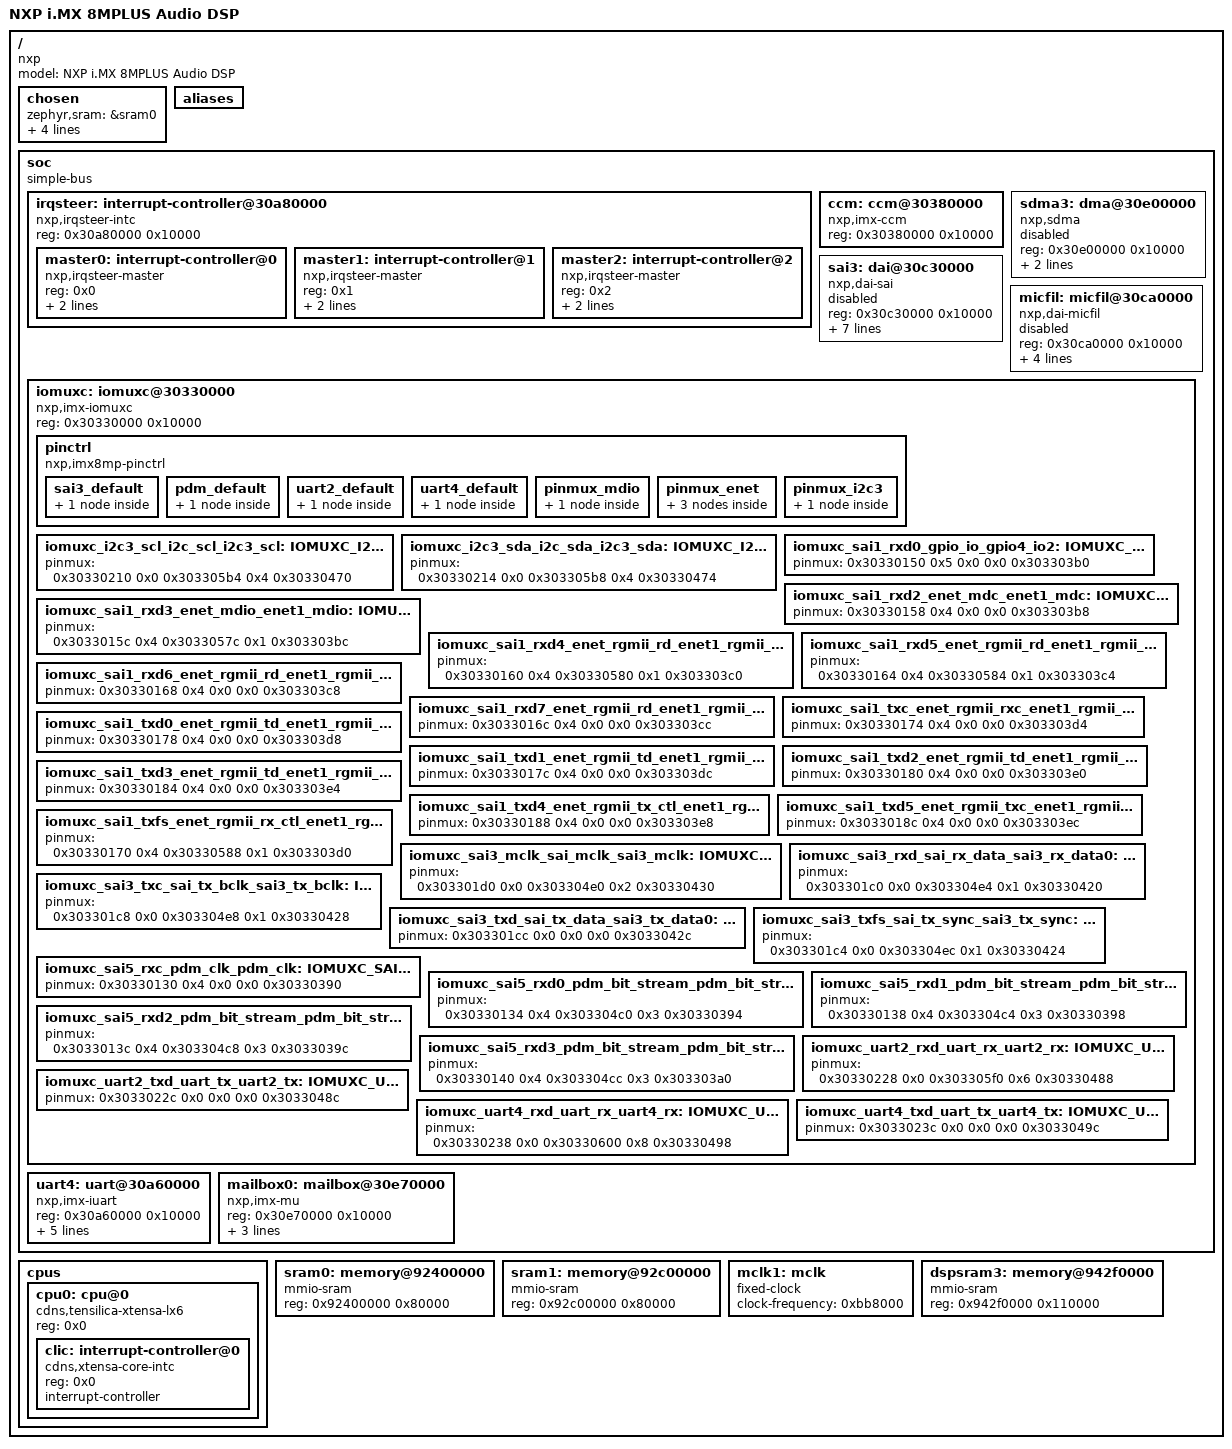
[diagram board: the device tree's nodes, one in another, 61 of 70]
/dts-v1/;

/ {
	#address-cells = < 0x1 >;
	#size-cells = < 0x1 >;
	model = "NXP i.MX 8MPLUS Audio DSP";
	compatible = "nxp";
	chosen {
		zephyr,sram = &sram0;
		zephyr,console = &uart4;
		zephyr,shell-uart = &uart4;
		zephyr,ipc_shm = &dspsram3;
		zephyr,ipc = &mailbox0;
	};
	aliases {
	};
	soc {
		#address-cells = < 0x1 >;
		#size-cells = < 0x1 >;
		compatible = "simple-bus";
		ranges;
		irqsteer: interrupt-controller@30a80000 {
			compatible = "nxp,irqsteer-intc";
			reg = < 0x30a80000 0x10000 >;
			#size-cells = < 0x0 >;
			#address-cells = < 0x1 >;
			master0: interrupt-controller@0 {
				compatible = "nxp,irqsteer-master";
				reg = < 0x0 >;
				interrupt-controller;
				#interrupt-cells = < 0x1 >;
				interrupts-extended = < &clic 0x13 0x0 0x0 >;
				phandle = < 0x26 >;
			};
			master1: interrupt-controller@1 {
				compatible = "nxp,irqsteer-master";
				reg = < 0x1 >;
				interrupt-controller;
				#interrupt-cells = < 0x1 >;
				interrupts-extended = < &clic 0x14 0x0 0x0 >;
				phandle = < 0x2 >;
			};
			master2: interrupt-controller@2 {
				compatible = "nxp,irqsteer-master";
				reg = < 0x2 >;
				interrupt-controller;
				#interrupt-cells = < 0x1 >;
				interrupts-extended = < &clic 0x15 0x0 0x0 >;
			};
		};
		ccm: ccm@30380000 {
			compatible = "nxp,imx-ccm";
			reg = < 0x30380000 0x10000 >;
			#clock-cells = < 0x3 >;
			phandle = < 0x27 >;
		};
		sdma3: dma@30e00000 {
			compatible = "nxp,sdma";
			reg = < 0x30e00000 0x10000 >;
			interrupt-parent = < &master1 >;
			interrupts = < 0x2 0x0 0x0 >;
			#dma-cells = < 0x2 >;
			status = "disabled";
			phandle = < 0x4 >;
		};
		sai3: dai@30c30000 {
			compatible = "nxp,dai-sai";
			reg = < 0x30c30000 0x10000 >;
			mclk-is-output;
			clocks = < &mclk1 >;
			clock-names = "mclk1";
			interrupt-parent = < &master1 >;
			interrupts = < 0x12 >;
			dai-index = < 0x3 >;
			dmas = < &sdma3 0x5 0x5 >, < &sdma3 0x4 0x5 >;
			dma-names = "tx", "rx";
			status = "disabled";
			pinctrl-0 = < &sai3_default >;
			pinctrl-names = "default";
		};
		micfil: micfil@30ca0000 {
			compatible = "nxp,dai-micfil";
			reg = < 0x30ca0000 0x10000 >;
			dai-index = < 0x2 >;
			dmas = < &sdma3 0x18 0x6 >;
			fifo-depth = < 0x20 >;
			status = "disabled";
			pinctrl-0 = < &pdm_default >;
			pinctrl-names = "default";
		};
		iomuxc: iomuxc@30330000 {
			compatible = "nxp,imx-iomuxc";
			reg = < 0x30330000 0x10000 >;
			status = "okay";
			pinctrl: pinctrl {
				status = "okay";
				compatible = "nxp,imx8mp-pinctrl";
				sai3_default: sai3_default {
					phandle = < 0x5 >;
					group0 {
						pinmux = < &iomuxc_sai3_txfs_sai_tx_sync_sai3_tx_sync >, < &iomuxc_sai3_txc_sai_tx_bclk_sai3_tx_bclk >, < &iomuxc_sai3_rxd_sai_rx_data_sai3_rx_data0 >, < &iomuxc_sai3_txd_sai_tx_data_sai3_tx_data0 >, < &iomuxc_sai3_mclk_sai_mclk_sai3_mclk >;
						bias-pull-up;
						slew-rate = "fast";
						drive-strength = "x6";
						input-schmitt-enable;
					};
				};
				pdm_default: pdm_default {
					phandle = < 0x6 >;
					group0 {
						pinmux = < &iomuxc_sai5_rxc_pdm_clk_pdm_clk >, < &iomuxc_sai5_rxd0_pdm_bit_stream_pdm_bit_stream0 >, < &iomuxc_sai5_rxd1_pdm_bit_stream_pdm_bit_stream1 >, < &iomuxc_sai5_rxd2_pdm_bit_stream_pdm_bit_stream2 >, < &iomuxc_sai5_rxd3_pdm_bit_stream_pdm_bit_stream3 >;
						bias-pull-up;
						slew-rate = "fast";
						drive-strength = "x6";
						input-schmitt-enable;
					};
				};
				uart2_default: uart2_default {
					group0 {
						pinmux = < &iomuxc_uart2_rxd_uart_rx_uart2_rx >, < &iomuxc_uart2_txd_uart_tx_uart2_tx >;
						bias-pull-up;
						slew-rate = "slow";
						drive-strength = "x1";
					};
				};
				uart4_default: uart4_default {
					phandle = < 0x28 >;
					group0 {
						pinmux = < &iomuxc_uart4_rxd_uart_rx_uart4_rx >, < &iomuxc_uart4_txd_uart_tx_uart4_tx >;
						bias-pull-up;
						slew-rate = "slow";
						drive-strength = "x1";
					};
				};
				pinmux_mdio: pinmux_mdio {
					group0 {
						pinmux = < &iomuxc_sai1_rxd2_enet_mdc_enet1_mdc >, < &iomuxc_sai1_rxd3_enet_mdio_enet1_mdio >;
						slew-rate = "slow";
						drive-strength = "x4";
					};
				};
				pinmux_enet: pinmux_enet {
					group0 {
						pinmux = < &iomuxc_sai1_rxd4_enet_rgmii_rd_enet1_rgmii_rd0 >, < &iomuxc_sai1_rxd5_enet_rgmii_rd_enet1_rgmii_rd1 >, < &iomuxc_sai1_rxd6_enet_rgmii_rd_enet1_rgmii_rd2 >, < &iomuxc_sai1_rxd7_enet_rgmii_rd_enet1_rgmii_rd3 >, < &iomuxc_sai1_txc_enet_rgmii_rxc_enet1_rgmii_rxc >, < &iomuxc_sai1_txfs_enet_rgmii_rx_ctl_enet1_rgmii_rx_ctl >;
						input-schmitt-enable;
						slew-rate = "fast";
						drive-strength = "x1";
					};
					group1 {
						pinmux = < &iomuxc_sai1_txd0_enet_rgmii_td_enet1_rgmii_td0 >, < &iomuxc_sai1_txd1_enet_rgmii_td_enet1_rgmii_td1 >, < &iomuxc_sai1_txd2_enet_rgmii_td_enet1_rgmii_td2 >, < &iomuxc_sai1_txd3_enet_rgmii_td_enet1_rgmii_td3 >, < &iomuxc_sai1_txd4_enet_rgmii_tx_ctl_enet1_rgmii_tx_ctl >, < &iomuxc_sai1_txd5_enet_rgmii_txc_enet1_rgmii_txc >;
						slew-rate = "fast";
						drive-strength = "x6";
					};
					group2 {
						pinmux = < &iomuxc_sai1_rxd0_gpio_io_gpio4_io2 >;
						slew-rate = "fast";
						drive-strength = "x1";
					};
				};
				pinmux_i2c3: pinmux_i2c3 {
					group0 {
						pinmux = < &iomuxc_i2c3_scl_i2c_scl_i2c3_scl >, < &iomuxc_i2c3_sda_i2c_sda_i2c3_sda >;
						bias-pull-up;
						input-schmitt-enable;
						slew-rate = "slow";
						drive-strength = "x4";
						input-enable;
					};
				};
			};
			iomuxc_i2c3_scl_i2c_scl_i2c3_scl: IOMUXC_I2C3_SCL_I2C_SCL_I2C3_SCL {
				pinmux = < 0x30330210 0x0 0x303305b4 0x4 0x30330470 >;
				phandle = < 0x24 >;
			};
			iomuxc_i2c3_sda_i2c_sda_i2c3_sda: IOMUXC_I2C3_SDA_I2C_SDA_I2C3_SDA {
				pinmux = < 0x30330214 0x0 0x303305b8 0x4 0x30330474 >;
				phandle = < 0x25 >;
			};
			iomuxc_sai1_rxd0_gpio_io_gpio4_io2: IOMUXC_SAI1_RXD0_GPIO_IO_GPIO4_IO2 {
				pinmux = < 0x30330150 0x5 0x0 0x0 0x303303b0 >;
				phandle = < 0x23 >;
			};
			iomuxc_sai1_rxd2_enet_mdc_enet1_mdc: IOMUXC_SAI1_RXD2_ENET_MDC_ENET1_MDC {
				pinmux = < 0x30330158 0x4 0x0 0x0 0x303303b8 >;
				phandle = < 0x15 >;
			};
			iomuxc_sai1_rxd3_enet_mdio_enet1_mdio: IOMUXC_SAI1_RXD3_ENET_MDIO_ENET1_MDIO {
				pinmux = < 0x3033015c 0x4 0x3033057c 0x1 0x303303bc >;
				phandle = < 0x16 >;
			};
			iomuxc_sai1_rxd4_enet_rgmii_rd_enet1_rgmii_rd0: IOMUXC_SAI1_RXD4_ENET_RGMII_RD_ENET1_RGMII_RD0 {
				pinmux = < 0x30330160 0x4 0x30330580 0x1 0x303303c0 >;
				phandle = < 0x17 >;
			};
			iomuxc_sai1_rxd5_enet_rgmii_rd_enet1_rgmii_rd1: IOMUXC_SAI1_RXD5_ENET_RGMII_RD_ENET1_RGMII_RD1 {
				pinmux = < 0x30330164 0x4 0x30330584 0x1 0x303303c4 >;
				phandle = < 0x18 >;
			};
			iomuxc_sai1_rxd6_enet_rgmii_rd_enet1_rgmii_rd2: IOMUXC_SAI1_RXD6_ENET_RGMII_RD_ENET1_RGMII_RD2 {
				pinmux = < 0x30330168 0x4 0x0 0x0 0x303303c8 >;
				phandle = < 0x19 >;
			};
			iomuxc_sai1_rxd7_enet_rgmii_rd_enet1_rgmii_rd3: IOMUXC_SAI1_RXD7_ENET_RGMII_RD_ENET1_RGMII_RD3 {
				pinmux = < 0x3033016c 0x4 0x0 0x0 0x303303cc >;
				phandle = < 0x1a >;
			};
			iomuxc_sai1_txc_enet_rgmii_rxc_enet1_rgmii_rxc: IOMUXC_SAI1_TXC_ENET_RGMII_RXC_ENET1_RGMII_RXC {
				pinmux = < 0x30330174 0x4 0x0 0x0 0x303303d4 >;
				phandle = < 0x1b >;
			};
			iomuxc_sai1_txd0_enet_rgmii_td_enet1_rgmii_td0: IOMUXC_SAI1_TXD0_ENET_RGMII_TD_ENET1_RGMII_TD0 {
				pinmux = < 0x30330178 0x4 0x0 0x0 0x303303d8 >;
				phandle = < 0x1d >;
			};
			iomuxc_sai1_txd1_enet_rgmii_td_enet1_rgmii_td1: IOMUXC_SAI1_TXD1_ENET_RGMII_TD_ENET1_RGMII_TD1 {
				pinmux = < 0x3033017c 0x4 0x0 0x0 0x303303dc >;
				phandle = < 0x1e >;
			};
			iomuxc_sai1_txd2_enet_rgmii_td_enet1_rgmii_td2: IOMUXC_SAI1_TXD2_ENET_RGMII_TD_ENET1_RGMII_TD2 {
				pinmux = < 0x30330180 0x4 0x0 0x0 0x303303e0 >;
				phandle = < 0x1f >;
			};
			iomuxc_sai1_txd3_enet_rgmii_td_enet1_rgmii_td3: IOMUXC_SAI1_TXD3_ENET_RGMII_TD_ENET1_RGMII_TD3 {
				pinmux = < 0x30330184 0x4 0x0 0x0 0x303303e4 >;
				phandle = < 0x20 >;
			};
			iomuxc_sai1_txd4_enet_rgmii_tx_ctl_enet1_rgmii_tx_ctl: IOMUXC_SAI1_TXD4_ENET_RGMII_TX_CTL_ENET1_RGMII_TX_CTL {
				pinmux = < 0x30330188 0x4 0x0 0x0 0x303303e8 >;
				phandle = < 0x21 >;
			};
			iomuxc_sai1_txd5_enet_rgmii_txc_enet1_rgmii_txc: IOMUXC_SAI1_TXD5_ENET_RGMII_TXC_ENET1_RGMII_TXC {
				pinmux = < 0x3033018c 0x4 0x0 0x0 0x303303ec >;
				phandle = < 0x22 >;
			};
			iomuxc_sai1_txfs_enet_rgmii_rx_ctl_enet1_rgmii_rx_ctl: IOMUXC_SAI1_TXFS_ENET_RGMII_RX_CTL_ENET1_RGMII_RX_CTL {
				pinmux = < 0x30330170 0x4 0x30330588 0x1 0x303303d0 >;
				phandle = < 0x1c >;
			};
			iomuxc_sai3_mclk_sai_mclk_sai3_mclk: IOMUXC_SAI3_MCLK_SAI_MCLK_SAI3_MCLK {
				pinmux = < 0x303301d0 0x0 0x303304e0 0x2 0x30330430 >;
				phandle = < 0xb >;
			};
			iomuxc_sai3_rxd_sai_rx_data_sai3_rx_data0: IOMUXC_SAI3_RXD_SAI_RX_DATA_SAI3_RX_DATA0 {
				pinmux = < 0x303301c0 0x0 0x303304e4 0x1 0x30330420 >;
				phandle = < 0x9 >;
			};
			iomuxc_sai3_txc_sai_tx_bclk_sai3_tx_bclk: IOMUXC_SAI3_TXC_SAI_TX_BCLK_SAI3_TX_BCLK {
				pinmux = < 0x303301c8 0x0 0x303304e8 0x1 0x30330428 >;
				phandle = < 0x8 >;
			};
			iomuxc_sai3_txd_sai_tx_data_sai3_tx_data0: IOMUXC_SAI3_TXD_SAI_TX_DATA_SAI3_TX_DATA0 {
				pinmux = < 0x303301cc 0x0 0x0 0x0 0x3033042c >;
				phandle = < 0xa >;
			};
			iomuxc_sai3_txfs_sai_tx_sync_sai3_tx_sync: IOMUXC_SAI3_TXFS_SAI_TX_SYNC_SAI3_TX_SYNC {
				pinmux = < 0x303301c4 0x0 0x303304ec 0x1 0x30330424 >;
				phandle = < 0x7 >;
			};
			iomuxc_sai5_rxc_pdm_clk_pdm_clk: IOMUXC_SAI5_RXC_PDM_CLK_PDM_CLK {
				pinmux = < 0x30330130 0x4 0x0 0x0 0x30330390 >;
				phandle = < 0xc >;
			};
			iomuxc_sai5_rxd0_pdm_bit_stream_pdm_bit_stream0: IOMUXC_SAI5_RXD0_PDM_BIT_STREAM_PDM_BIT_STREAM0 {
				pinmux = < 0x30330134 0x4 0x303304c0 0x3 0x30330394 >;
				phandle = < 0xd >;
			};
			iomuxc_sai5_rxd1_pdm_bit_stream_pdm_bit_stream1: IOMUXC_SAI5_RXD1_PDM_BIT_STREAM_PDM_BIT_STREAM1 {
				pinmux = < 0x30330138 0x4 0x303304c4 0x3 0x30330398 >;
				phandle = < 0xe >;
			};
			iomuxc_sai5_rxd2_pdm_bit_stream_pdm_bit_stream2: IOMUXC_SAI5_RXD2_PDM_BIT_STREAM_PDM_BIT_STREAM2 {
				pinmux = < 0x3033013c 0x4 0x303304c8 0x3 0x3033039c >;
				phandle = < 0xf >;
			};
			iomuxc_sai5_rxd3_pdm_bit_stream_pdm_bit_stream3: IOMUXC_SAI5_RXD3_PDM_BIT_STREAM_PDM_BIT_STREAM3 {
				pinmux = < 0x30330140 0x4 0x303304cc 0x3 0x303303a0 >;
				phandle = < 0x10 >;
			};
			iomuxc_uart2_rxd_uart_rx_uart2_rx: IOMUXC_UART2_RXD_UART_RX_UART2_RX {
				pinmux = < 0x30330228 0x0 0x303305f0 0x6 0x30330488 >;
				phandle = < 0x11 >;
			};
			iomuxc_uart2_txd_uart_tx_uart2_tx: IOMUXC_UART2_TXD_UART_TX_UART2_TX {
				pinmux = < 0x3033022c 0x0 0x0 0x0 0x3033048c >;
				phandle = < 0x12 >;
			};
			iomuxc_uart4_rxd_uart_rx_uart4_rx: IOMUXC_UART4_RXD_UART_RX_UART4_RX {
				pinmux = < 0x30330238 0x0 0x30330600 0x8 0x30330498 >;
				phandle = < 0x13 >;
			};
			iomuxc_uart4_txd_uart_tx_uart4_tx: IOMUXC_UART4_TXD_UART_TX_UART4_TX {
				pinmux = < 0x3033023c 0x0 0x0 0x0 0x3033049c >;
				phandle = < 0x14 >;
			};
		};
		uart4: uart@30a60000 {
			compatible = "nxp,imx-iuart";
			reg = < 0x30a60000 0x10000 >;
			interrupt-parent = < &master0 >;
			interrupts = < 0x1d 0x0 0x0 >;
			clocks = < &ccm 0x803 0x6c 0x18 >;
			status = "okay";
			current-speed = < 0x1c200 >;
			pinctrl-0 = < &uart4_default >;
			pinctrl-names = "default";
		};
		mailbox0: mailbox@30e70000 {
			compatible = "nxp,imx-mu";
			reg = < 0x30e70000 0x10000 >;
			interrupt-parent = < &clic >;
			interrupts = < 0x7 0x0 0x0 >;
			rdc = < 0x0 >;
			status = "okay";
		};
	};
	cpus {
		#address-cells = < 0x1 >;
		#size-cells = < 0x0 >;
		cpu0: cpu@0 {
			device_type = "cpu";
			compatible = "cdns,tensilica-xtensa-lx6";
			reg = < 0x0 >;
			#address-cells = < 0x1 >;
			#size-cells = < 0x0 >;
			clic: interrupt-controller@0 {
				compatible = "cdns,xtensa-core-intc";
				reg = < 0x0 >;
				interrupt-controller;
				#interrupt-cells = < 0x3 >;
				phandle = < 0x1 >;
			};
		};
	};
	sram0: memory@92400000 {
		device_type = "memory";
		compatible = "mmio-sram";
		reg = < 0x92400000 0x80000 >;
	};
	sram1: memory@92c00000 {
		device_type = "memory";
		compatible = "mmio-sram";
		reg = < 0x92c00000 0x80000 >;
	};
	mclk1: mclk {
		compatible = "fixed-clock";
		#clock-cells = < 0x0 >;
		clock-frequency = < 0xbb8000 >;
		phandle = < 0x3 >;
	};
	dspsram3: memory@942f0000 {
		compatible = "mmio-sram";
		reg = < 0x942f0000 0x110000 >;
	};
};
